AUTOSAR XML (schema 4.0)
standard types defined: float32, float64, sint16, sint32, sint8, uint16, uint32, uint8, void, boolean
package /ImplDataTypes
  impl type MultiStateBtnType: implementation-data-type=uint8, type-emitter=RTE
package /MappingSets
  data type mapping set MappingSet
package /PortInterfaces/SenderReceiver
  sender receiver interface SrIf_SeatCtrlBtns
    data HeightBtnState: type=MultiStateBtnType
    data InclineBtnState: type=MultiStateBtnType
    data SlideBtnState: type=MultiStateBtnType
  sender receiver interface SrIf_SeatCtrlData
    data Height: type=uint8
    data Incline: type=uint8
    data Slide: type=uint8
package /SoftwareComponents
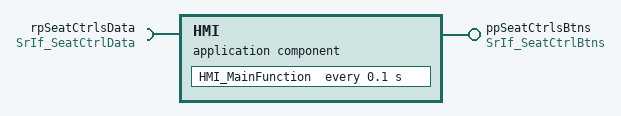
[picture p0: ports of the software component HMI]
  application sw component type HMI
    provide port ppSeatCtrlsBtns: provided-interface=SrIf_SeatCtrlBtns
    require port rpSeatCtrlsData: required-interface=SrIf_SeatCtrlData
    behavior Ibhv_HMI: data-type-mapping=MappingSet, handle-termination-and-restart=NO-SUPPORT
      timing event TE_HMI_MainFunction_100ms: start-on-event=HMI_MainFunction, period=0.1
      runnable HMI_MainFunction
        data-receive-point-by-arguments:
          access DRP_rpSeatCtrlsData_Height: accessed-variable=rpSeatCtrlsData.Height
          access DRP_rpSeatCtrlsData_Incline: accessed-variable=rpSeatCtrlsData.Incline
          access DRP_rpSeatCtrlsData_Slide: accessed-variable=rpSeatCtrlsData.Slide
        data-send-points:
          access DSP_ppSeatCtrlsBtns_HeightBtnState: accessed-variable=ppSeatCtrlsBtns.HeightBtnState
          access DSP_ppSeatCtrlsBtns_InclineBtnState: accessed-variable=ppSeatCtrlsBtns.InclineBtnState
          access DSP_ppSeatCtrlsBtns_SlideBtnState: accessed-variable=ppSeatCtrlsBtns.SlideBtnState
  swc implementation Impl_HMI: programming-language=C, sw-version=1.0.0, vendor-id=255, behavior=Ibhv_HMI
    code-descriptors:
      code Code: artifact-descriptors=autosar-engineering-object={short-label=SWC.c, category=SWSRC}
    resource consumption ResourceConsumption
  swc implementation Impl_SeatManager: programming-language=C, sw-version=1.0.0, vendor-id=255, behavior=Ibhv_SeatManager
    code-descriptors:
      code Code: artifact-descriptors=autosar-engineering-object={short-label=SWC.c, category=SWSRC}
    resource consumption ResourceConsumption
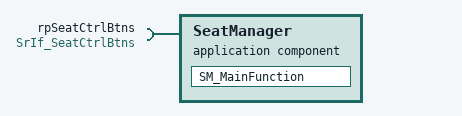
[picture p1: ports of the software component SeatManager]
  application sw component type SeatManager
    require port rpSeatCtrlBtns: required-interface=SrIf_SeatCtrlBtns
    behavior Ibhv_SeatManager: data-type-mapping=MappingSet, handle-termination-and-restart=NO-SUPPORT
      data received event DRE_rpSeatCtrlBtns_HeightBtnState: start-on-event=SM_MainFunction, data=rpSeatCtrlBtns.HeightBtnState
      data received event DRE_rpSeatCtrlBtns_InclineBtnState: start-on-event=SM_MainFunction, data=rpSeatCtrlBtns.InclineBtnState
      data received event DRE_rpSeatCtrlBtns_SlideBtnState: start-on-event=SM_MainFunction, data=rpSeatCtrlBtns.SlideBtnState
      runnable SM_MainFunction
        data-receive-point-by-arguments:
          access DRP_rpSeatCtrlBtns_HeightBtnState: accessed-variable=rpSeatCtrlBtns.HeightBtnState
          access DRP_rpSeatCtrlBtns_InclineBtnState: accessed-variable=rpSeatCtrlBtns.InclineBtnState
          access DRP_rpSeatCtrlBtns_SlideBtnState: accessed-variable=rpSeatCtrlBtns.SlideBtnState
package /Compositions
  composition sw component type Task2Composition
    component HMI: type=HMI
    component SeatManager: type=SeatManager
    connect HMI.ppSeatCtrlsBtns -> SeatManager.rpSeatCtrlBtns
